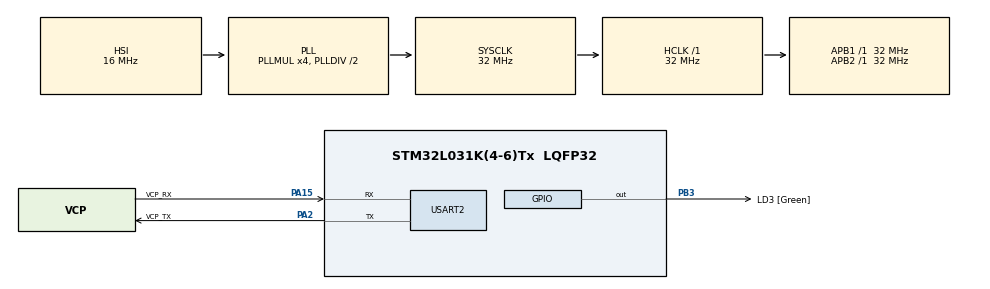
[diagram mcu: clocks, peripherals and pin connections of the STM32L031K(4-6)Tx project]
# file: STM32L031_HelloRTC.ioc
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Mcu.Family=STM32L0
Mcu.Name=STM32L031K(4-6)Tx
Mcu.Package=LQFP32
PA13.GPIO_Label=TMS
PA13.Mode=Serial_Wire
PA13.Signal=SYS_SWDIO
PA14.GPIO_Label=TCK
PA14.Mode=Serial_Wire
PA14.Signal=SYS_SWCLK
PA15.GPIO_Label=VCP_RX
PA15.Mode=Asynchronous
PA15.Signal=USART2_RX
PA2.GPIO_Label=VCP_TX
PA2.Mode=Asynchronous
PA2.Signal=USART2_TX
PB3.GPIO_Label=LD3 [Green]
PB3.Signal=GPIO_Output
PC14-OSC32_IN.Mode=LSE-External-Oscillator
PC14-OSC32_IN.Signal=RCC_OSC32_IN
PC15-OSC32_OUT.Mode=LSE-External-Oscillator
PC15-OSC32_OUT.Signal=RCC_OSC32_OUT
ProjectManager.HeapSize=0x200
ProjectManager.StackSize=0x400
ProjectManager.TargetToolchain=STM32CubeIDE
RCC.AHBFreq_Value=32000000
RCC.APB1Freq_Value=32000000
RCC.APB1TimFreq_Value=32000000
RCC.APB2Freq_Value=32000000
RCC.APB2TimFreq_Value=32000000
RCC.HCLKFreq_Value=32000000
RCC.HSE_VALUE=8000000
RCC.HSI16_VALUE=16000000
RCC.HSI48_VALUE=48000000
RCC.HSI_VALUE=16000000
RCC.MSI_VALUE=2097000
RCC.PLLMUL=RCC_PLLMUL_4
RCC.RTCClockSelection=RCC_RTCCLKSOURCE_LSE
RCC.SYSCLKFreq_VALUE=32000000
RCC.SYSCLKSource=RCC_SYSCLKSOURCE_PLLCLK
RCC.VCOOutputFreq_Value=64000000
USART2.VirtualMode-Asynchronous=VM_ASYNC
VP_RTC_VS_RTC_Activate.Mode=RTC_Enabled
board=NUCLEO-L031K6

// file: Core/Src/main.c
/* USER CODE BEGIN Header */
/**
  ******************************************************************************
  * @file           : main.c
  * @brief          : Main program body
  ******************************************************************************
  * @attention
  *
  * Copyright (c) 2022 STMicroelectronics.
  * All rights reserved.
  *
  * This software is licensed under terms that can be found in the LICENSE file
  * in the root directory of this software component.
  * If no LICENSE file comes with this software, it is provided AS-IS.
  *
  ******************************************************************************
  */
/* USER CODE END Header */
#include "main.h"

/* USER CODE BEGIN Includes */
#include "build_defs.h"
/* USER CODE END Includes */

RTC_HandleTypeDef hrtc;

UART_HandleTypeDef huart2;

/* USER CODE BEGIN PV */

/*
 * could be filled with:
 *  60 min
 *  24 hours
 *  31 date
 *  12 month
 *   7 weekday
 * ----------------
 * 134 leds
 *
 * possibly:
 *   2 am/pm
 * 7/8 year (0-100)
 * ----------------
 *   0-1 left, maybe low battery level?
 */

// mapping of time and date to led index
const uint8_t secondsmap[] = {0, 0, 0, 0, 0, 0, 0, 0, 0, 0, 0, 0, 0, 0, 0, 0, 0, 0, 0, 0, 0, 0, 0, 0, 0, 0, 0, 0, 0, 0, 0, 0, 0, 0, 0, 0, 0, 0, 0, 0, 0, 0, 0, 0, 0, 0, 0, 0, 0, 0, 0, 0, 0, 0, 0, 0, 0, 0, 0, 0};
const uint8_t minutesmap[] = {0, 0, 0, 0, 0, 0, 0, 0, 0, 0, 0, 0, 0, 0, 0, 0, 0, 0, 0, 0, 0, 0, 0, 0, 0, 0, 0, 0, 0, 0, 0, 0, 0, 0, 0, 0, 0, 0, 0, 0, 0, 0, 0, 0, 0, 0, 0, 0, 0, 0, 0, 0, 0, 0, 0, 0, 0, 0, 0, 0};
const uint8_t hoursmap[] = {0, 0, 0, 0, 0, 0, 0, 0, 0, 0, 0, 0, 0, 0, 0, 0, 0, 0, 0, 0, 0, 0, 0, 0};
const uint8_t weekdaysmap[] = {0, 0, 0, 0, 0, 0, 0};
const uint8_t datesmap[] = {0, 0, 0, 0, 0, 0, 0, 0, 0, 0, 0, 0, 0, 0, 0, 0, 0, 0, 0, 0, 0, 0, 0, 0, 0, 0, 0, 0, 0, 0, 0};
const uint8_t monthsmap[] = {0, 0, 0, 0, 0, 0, 0, 0, 0, 0, 0, 0};
const uint8_t yearsmap[] = {0, 0, 0, 0, 0, 0, 0, 0, 0, 0, 0, 0}; // bitmask for up to 4095. 2022 = 0b0111 1110 0110
/* USER CODE END PV */

void SystemClock_Config(void);
static void MX_GPIO_Init(void);
static void MX_USART2_UART_Init(void);
static void MX_RTC_Init(void);
/* USER CODE BEGIN PFP */
static void MAX_Set_Rtc(void);
//static bool MAX_Is_Dst(RTC_TimeTypeDef * sTime);
/* USER CODE END PFP */

int main(void)
{

  /* MCU Configuration--------------------------------------------------------*/

  /* Reset of all peripherals, Initializes the Flash interface and the Systick. */
  HAL_Init();

  /* Configure the system clock */
  SystemClock_Config();

  /* Initialize all configured peripherals */
  MX_GPIO_Init();
  MX_USART2_UART_Init();
  MX_RTC_Init();
  /* USER CODE BEGIN 2 */

  MAX_Set_Rtc();

  /* USER CODE END 2 */

  /* Infinite loop */
  /* USER CODE BEGIN WHILE */
  while (1)
  {
    // get time and date from rtc
    RTC_TimeTypeDef time;
    RTC_DateTypeDef date;
    HAL_RTC_GetTime(&hrtc, &time, RTC_FORMAT_BIN);
    HAL_RTC_GetDate(&hrtc, &date, RTC_FORMAT_BIN);

    /*
    // currently daylight saving is not accounted for!
    if (MAX_Is_Dst(&date) && !isDst) {
      // time changed summer to winter
    } else if () {
      // time changed winter to summer
    }
    */

    HAL_GPIO_TogglePin(GPIOB, GPIO_PIN_3);
    HAL_Delay(1000);
    /* USER CODE END WHILE */

  }
}

void SystemClock_Config(void)
{
  RCC_OscInitTypeDef RCC_OscInitStruct = {0};
  RCC_ClkInitTypeDef RCC_ClkInitStruct = {0};
  RCC_PeriphCLKInitTypeDef PeriphClkInit = {0};

  /** Configure the main internal regulator output voltage
  */
  __HAL_PWR_VOLTAGESCALING_CONFIG(PWR_REGULATOR_VOLTAGE_SCALE1);
  /** Configure LSE Drive Capability
  */
  HAL_PWR_EnableBkUpAccess();
  __HAL_RCC_LSEDRIVE_CONFIG(RCC_LSEDRIVE_LOW);
  /** Initializes the RCC Oscillators according to the specified parameters
  * in the RCC_OscInitTypeDef structure.
  */
  RCC_OscInitStruct.OscillatorType = RCC_OSCILLATORTYPE_HSI|RCC_OSCILLATORTYPE_LSE;
  RCC_OscInitStruct.LSEState = RCC_LSE_ON;
  RCC_OscInitStruct.HSIState = RCC_HSI_ON;
  RCC_OscInitStruct.HSICalibrationValue = RCC_HSICALIBRATION_DEFAULT;
  RCC_OscInitStruct.PLL.PLLState = RCC_PLL_ON;
  RCC_OscInitStruct.PLL.PLLSource = RCC_PLLSOURCE_HSI;
  RCC_OscInitStruct.PLL.PLLMUL = RCC_PLLMUL_4;
  RCC_OscInitStruct.PLL.PLLDIV = RCC_PLLDIV_2;
  if (HAL_RCC_OscConfig(&RCC_OscInitStruct) != HAL_OK)
  {
    Error_Handler();
  }
  /** Initializes the CPU, AHB and APB buses clocks
  */
  RCC_ClkInitStruct.ClockType = RCC_CLOCKTYPE_HCLK|RCC_CLOCKTYPE_SYSCLK
                              |RCC_CLOCKTYPE_PCLK1|RCC_CLOCKTYPE_PCLK2;
  RCC_ClkInitStruct.SYSCLKSource = RCC_SYSCLKSOURCE_PLLCLK;
  RCC_ClkInitStruct.AHBCLKDivider = RCC_SYSCLK_DIV1;
  RCC_ClkInitStruct.APB1CLKDivider = RCC_HCLK_DIV1;
  RCC_ClkInitStruct.APB2CLKDivider = RCC_HCLK_DIV1;

  if (HAL_RCC_ClockConfig(&RCC_ClkInitStruct, FLASH_LATENCY_1) != HAL_OK)
  {
    Error_Handler();
  }
  PeriphClkInit.PeriphClockSelection = RCC_PERIPHCLK_USART2|RCC_PERIPHCLK_RTC;
  PeriphClkInit.Usart2ClockSelection = RCC_USART2CLKSOURCE_PCLK1;
  PeriphClkInit.RTCClockSelection = RCC_RTCCLKSOURCE_LSE;
  if (HAL_RCCEx_PeriphCLKConfig(&PeriphClkInit) != HAL_OK)
  {
    Error_Handler();
  }
}

static void MX_RTC_Init(void)
{

  /** Initialize RTC Only
  */
  hrtc.Instance = RTC;
  hrtc.Init.HourFormat = RTC_HOURFORMAT_24;
  hrtc.Init.AsynchPrediv = 127;
  hrtc.Init.SynchPrediv = 255;
  hrtc.Init.OutPut = RTC_OUTPUT_DISABLE;
  hrtc.Init.OutPutRemap = RTC_OUTPUT_REMAP_NONE;
  hrtc.Init.OutPutPolarity = RTC_OUTPUT_POLARITY_HIGH;
  hrtc.Init.OutPutType = RTC_OUTPUT_TYPE_OPENDRAIN;
  if (HAL_RTC_Init(&hrtc) != HAL_OK)
  {
    Error_Handler();
  }

}

static void MX_USART2_UART_Init(void)
{

  huart2.Instance = USART2;
  huart2.Init.BaudRate = 115200;
  huart2.Init.WordLength = UART_WORDLENGTH_8B;
  huart2.Init.StopBits = UART_STOPBITS_1;
  huart2.Init.Parity = UART_PARITY_NONE;
  huart2.Init.Mode = UART_MODE_TX_RX;
  huart2.Init.HwFlowCtl = UART_HWCONTROL_NONE;
  huart2.Init.OverSampling = UART_OVERSAMPLING_16;
  huart2.Init.OneBitSampling = UART_ONE_BIT_SAMPLE_DISABLE;
  huart2.AdvancedInit.AdvFeatureInit = UART_ADVFEATURE_NO_INIT;
  if (HAL_UART_Init(&huart2) != HAL_OK)
  {
    Error_Handler();
  }

}

static void MX_GPIO_Init(void)
{
  GPIO_InitTypeDef GPIO_InitStruct = {0};

  /* GPIO Ports Clock Enable */
  __HAL_RCC_GPIOC_CLK_ENABLE();
  __HAL_RCC_GPIOA_CLK_ENABLE();
  __HAL_RCC_GPIOB_CLK_ENABLE();

  /*Configure GPIO pin Output Level */
  HAL_GPIO_WritePin(LD3_GPIO_Port, LD3_Pin, GPIO_PIN_RESET);

  /*Configure GPIO pin : LD3_Pin */
  GPIO_InitStruct.Pin = LD3_Pin;
  GPIO_InitStruct.Mode = GPIO_MODE_OUTPUT_PP;
  GPIO_InitStruct.Pull = GPIO_NOPULL;
  GPIO_InitStruct.Speed = GPIO_SPEED_FREQ_LOW;
  HAL_GPIO_Init(LD3_GPIO_Port, &GPIO_InitStruct);

}

/* USER CODE BEGIN 4 */
/**
  * @brief Set the RTC to build time
  * @param None
  * @retval None
  */
static void MAX_Set_Rtc(void)
{
  // with the build_defs.h this sets the rtc to build time
  // it will lag the real time just by a few seconds

  RTC_TimeTypeDef time;
  time.Hours = BUILD_HOUR;
  time.Minutes = BUILD_MIN;
  time.Seconds = BUILD_SEC;
  HAL_RTC_SetTime(&hrtc, &time, RTC_FORMAT_BIN);

  // same with the date
  RTC_DateTypeDef date;
  date.Year = BUILD_YEAR_SHORT;
  date.Month = BUILD_MONTH;
  date.Date = BUILD_DAY;
  // the weekday is calculated (meh)
  int year = BUILD_YEAR;
  int month = BUILD_MONTH;
  int day = BUILD_DAY;
  if (month < 3) {
    day = day + year;
    year--;
  } else {
    day = day + year - 2;
  }
  date.WeekDay = ((int)(23 * month/9) + day + 4 + (int)(year/4) - (int)(year/100) + (int)(year/400)) % 7;
  // correct for sunday
  // 1 = monday, 7 = sunday
  if (date.WeekDay == 0) {
    date.WeekDay = 7;
  }
  HAL_RTC_SetDate(&hrtc, &date, RTC_FORMAT_BIN);
}

/**
  * @brief Check if date is within german daylight saving time
  * @param None
  * @retval true, if summer time
  */
/*
static bool MAX_Is_Dst(RTC_TimeDateDef * sDate)
{
  uint8_t wday, month;    // locals for faster access

  month = sDate->Month;

  if( month < 3 || month > 10 ) {   // month 1, 2, 11, 12
    return false;         // -> Winter
  }

  wday  = sDate->WeekDay;
  // adjust for sunday
  if (wday == 7) {
    wday = 0;
  }

  if( t->mday - wday >= 25 && (wday || t->hour >= 2) ) { // after last Sunday 2:00
    if( month == 10 ) {       // October -> Winter
      return false;
    }
  } else {              // before last Sunday 2:00
    if( month == 3 ) {        // March -> Winter
      return false;
    }
  }

  return true;
}
*/
/* USER CODE END 4 */

void Error_Handler(void)
{
  __disable_irq();
  while (1)
  {
  }
}
